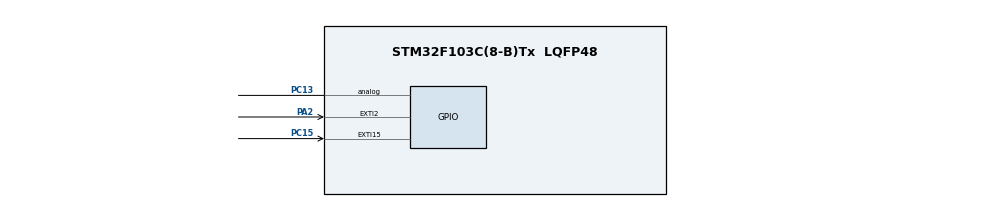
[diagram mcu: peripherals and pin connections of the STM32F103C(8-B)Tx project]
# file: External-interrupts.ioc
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Mcu.Family=STM32F1
Mcu.Name=STM32F103C(8-B)Tx
Mcu.Package=LQFP48
NVIC.EXTI15_10_IRQn=true\:0\:0\:false\:false\:true\:true\:true\:true
NVIC.PriorityGroup=NVIC_PRIORITYGROUP_4
PA2.Signal=GPXTI2
PC13-TAMPER-RTC.Signal=GPIO_Analog
PC15-OSC32_OUT.GPIO_ModeDefaultEXTI=GPIO_MODE_IT_FALLING
PC15-OSC32_OUT.GPIO_PuPd=GPIO_PULLUP
PC15-OSC32_OUT.Signal=GPXTI15
PD0-OSC_IN.Mode=HSE-External-Clock-Source
PD0-OSC_IN.Signal=RCC_OSC_IN
PD1-OSC_OUT.Mode=HSE-External-Clock-Source
PD1-OSC_OUT.Signal=RCC_OSC_OUT
ProjectManager.HeapSize=0x200
ProjectManager.StackSize=0x400
ProjectManager.TargetToolchain=STM32CubeIDE
RCC.APB1Freq_Value=8000000
RCC.APB2Freq_Value=8000000
RCC.PLLSourceVirtual=RCC_PLLSOURCE_HSE
RCC.SYSCLKSource=RCC_SYSCLKSOURCE_HSE
RCC.USBFreq_Value=16000000
VP_SYS_VS_ND.Mode=No_Debug
board=custom

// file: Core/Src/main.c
/* USER CODE BEGIN Header */
/**
  ******************************************************************************
  * @file           : main.c
  * @brief          : Main program body
  ******************************************************************************
  * @attention
  *
  * Copyright (c) 2024 STMicroelectronics.
  * All rights reserved.
  *
  * This software is licensed under terms that can be found in the LICENSE file
  * in the root directory of this software component.
  * If no LICENSE file comes with this software, it is provided AS-IS.
  *
  ******************************************************************************
  */
/* USER CODE END Header */
#include "main.h"

void SystemClock_Config(void);
static void MX_GPIO_Init(void);

/* USER CODE BEGIN 0 */

static uint8_t ledStatus = GPIO_PIN_SET;
void HAL_GPIO_EXTI_Callback(uint16_t GPIO_Pin){
	ledStatus =~ ledStatus;
}

/* USER CODE END 0 */

int main(void)
{

  /* MCU Configuration--------------------------------------------------------*/

  /* Reset of all peripherals, Initializes the Flash interface and the Systick. */
  HAL_Init();

  /* Configure the system clock */
  SystemClock_Config();

  /* Initialize all configured peripherals */
  MX_GPIO_Init();

  /* Infinite loop */
  while (1)
  {
	  HAL_GPIO_WritePin(GPIOC,GPIO_PIN_13,ledStatus);

  }
}

void SystemClock_Config(void)
{
  RCC_OscInitTypeDef RCC_OscInitStruct = {0};
  RCC_ClkInitTypeDef RCC_ClkInitStruct = {0};

  /** Initializes the RCC Oscillators according to the specified parameters
  * in the RCC_OscInitTypeDef structure.
  */
  RCC_OscInitStruct.OscillatorType = RCC_OSCILLATORTYPE_HSE;
  RCC_OscInitStruct.HSEState = RCC_HSE_BYPASS;
  RCC_OscInitStruct.PLL.PLLState = RCC_PLL_NONE;
  if (HAL_RCC_OscConfig(&RCC_OscInitStruct) != HAL_OK)
  {
    Error_Handler();
  }

  /** Initializes the CPU, AHB and APB buses clocks
  */
  RCC_ClkInitStruct.ClockType = RCC_CLOCKTYPE_HCLK|RCC_CLOCKTYPE_SYSCLK
                              |RCC_CLOCKTYPE_PCLK1|RCC_CLOCKTYPE_PCLK2;
  RCC_ClkInitStruct.SYSCLKSource = RCC_SYSCLKSOURCE_HSE;
  RCC_ClkInitStruct.AHBCLKDivider = RCC_SYSCLK_DIV1;
  RCC_ClkInitStruct.APB1CLKDivider = RCC_HCLK_DIV1;
  RCC_ClkInitStruct.APB2CLKDivider = RCC_HCLK_DIV1;

  if (HAL_RCC_ClockConfig(&RCC_ClkInitStruct, FLASH_LATENCY_0) != HAL_OK)
  {
    Error_Handler();
  }
}

static void MX_GPIO_Init(void)
{
  GPIO_InitTypeDef GPIO_InitStruct = {0};

  /* GPIO Ports Clock Enable */
  __HAL_RCC_GPIOC_CLK_ENABLE();
  __HAL_RCC_GPIOD_CLK_ENABLE();
  __HAL_RCC_GPIOA_CLK_ENABLE();

  /*Configure GPIO pin : PC13 */
  GPIO_InitStruct.Pin = GPIO_PIN_13;
  GPIO_InitStruct.Mode = GPIO_MODE_ANALOG;
  HAL_GPIO_Init(GPIOC, &GPIO_InitStruct);

  /*Configure GPIO pin : PC15 */
  GPIO_InitStruct.Pin = GPIO_PIN_15;
  GPIO_InitStruct.Mode = GPIO_MODE_IT_FALLING;
  GPIO_InitStruct.Pull = GPIO_PULLUP;
  HAL_GPIO_Init(GPIOC, &GPIO_InitStruct);

  /*Configure GPIO pin : PA2 */
  GPIO_InitStruct.Pin = GPIO_PIN_2;
  GPIO_InitStruct.Mode = GPIO_MODE_IT_RISING;
  GPIO_InitStruct.Pull = GPIO_NOPULL;
  HAL_GPIO_Init(GPIOA, &GPIO_InitStruct);

  /* EXTI interrupt init*/
  HAL_NVIC_SetPriority(EXTI15_10_IRQn, 0, 0);
  HAL_NVIC_EnableIRQ(EXTI15_10_IRQn);

}

void Error_Handler(void)
{
  __disable_irq();
  while (1)
  {
  }
}
